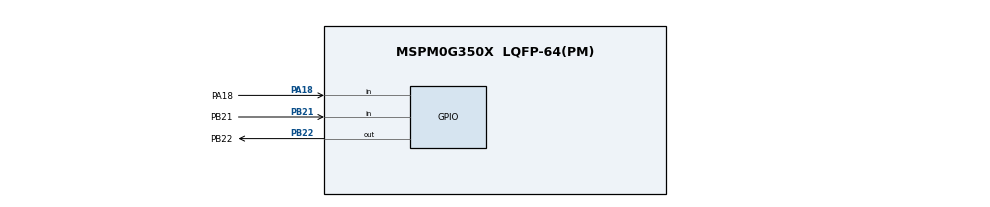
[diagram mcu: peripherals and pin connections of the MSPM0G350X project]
/**
 * @cliArgs --device "MSPM0G350X" --part "Default" --package "LQFP-64(PM)" --product "mspm0_sdk@2.09.00.01"
 * @versions {"tool":"1.25.0+4268"}
 */

/**
 * Import the modules used in this configuration.
 */
const GPIO          = scripting.addModule("/ti/driverlib/GPIO", {}, false);
const GPIO1         = GPIO.addInstance();
const GPIO2         = GPIO.addInstance();
const SYSCTL        = scripting.addModule("/ti/driverlib/SYSCTL");
const TIMER         = scripting.addModule("/ti/driverlib/TIMER", {}, false);
const TIMER1        = TIMER.addInstance();
const ProjectConfig = scripting.addModule("/ti/project_config/ProjectConfig");

/**
 * Write custom configuration values to the imported modules.
 */
GPIO1.$name                              = "KEY";
GPIO1.associatedPins.create(2);
GPIO1.associatedPins[0].$name            = "PA18";
GPIO1.associatedPins[0].direction        = "INPUT";
GPIO1.associatedPins[0].assignedPort     = "PORTA";
GPIO1.associatedPins[0].assignedPin      = "18";
GPIO1.associatedPins[0].polarity         = "RISE";
GPIO1.associatedPins[0].pin.$assign      = "PA18";
GPIO1.associatedPins[1].$name            = "PB21";
GPIO1.associatedPins[1].direction        = "INPUT";
GPIO1.associatedPins[1].internalResistor = "PULL_UP";
GPIO1.associatedPins[1].assignedPort     = "PORTB";
GPIO1.associatedPins[1].assignedPin      = "21";
GPIO1.associatedPins[1].polarity         = "FALL";
GPIO1.associatedPins[1].pin.$assign      = "PB21";

const Board = scripting.addModule("/ti/driverlib/Board", {}, false);

GPIO2.$name                              = "LED";
GPIO2.associatedPins[0].$name            = "PB22";
GPIO2.associatedPins[0].internalResistor = "PULL_UP";
GPIO2.associatedPins[0].pin.$assign      = "PB22";


TIMER1.$name              = "KeyScan_TIMER";
TIMER1.timerMode          = "PERIODIC";
TIMER1.interrupts         = ["ZERO"];
TIMER1.timerPeriod        = "1ms";
TIMER1.timerClkDiv        = 8;
TIMER1.peripheral.$assign = "TIMG0";

ProjectConfig.deviceSpin = "MSPM0G3507";

/**
 * Pinmux solution for unlocked pins/peripherals. This ensures that minor changes to the automatic solver in a future
 * version of the tool will not impact the pinmux you originally saw.  These lines can be completely deleted in order to
 * re-solve from scratch.
 */
Board.peripheral.$suggestSolution          = "DEBUGSS";
Board.peripheral.swclkPin.$suggestSolution = "PA20";
Board.peripheral.swdioPin.$suggestSolution = "PA19";
SYSCTL.peripheral.$suggestSolution         = "SYSCTL";
